AUTOSAR XML (schema 4-0-3)
package /ComponentTypes
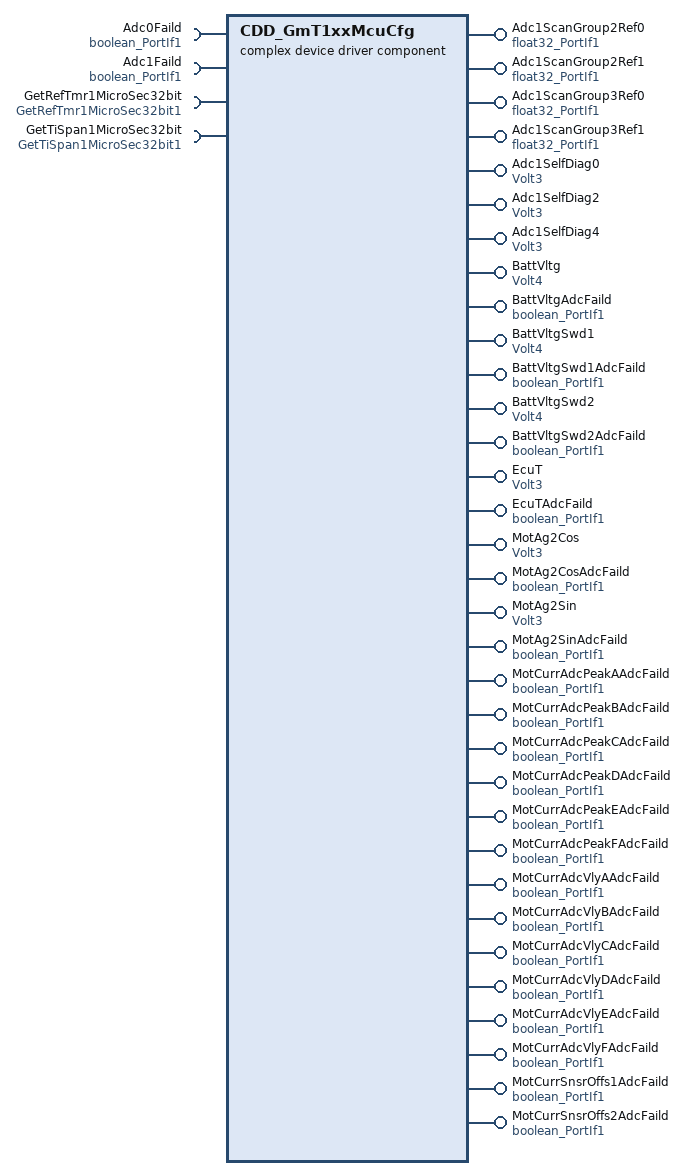
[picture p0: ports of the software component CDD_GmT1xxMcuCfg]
  complex device driver sw component type CDD_GmT1xxMcuCfg
    33 x provide port:
      Adc1ScanGroup2Ref0: nonqueued-sender-com-spec{data-element=Val, init-value=0}, provided-interface=float32_PortIf1
      Adc1ScanGroup2Ref1: nonqueued-sender-com-spec{data-element=Val, init-value=0}, provided-interface=float32_PortIf1
      Adc1ScanGroup3Ref0: nonqueued-sender-com-spec{data-element=Val, init-value=0}, provided-interface=float32_PortIf1
      Adc1ScanGroup3Ref1: nonqueued-sender-com-spec{data-element=Val, init-value=0}, provided-interface=float32_PortIf1
      Adc1SelfDiag0: nonqueued-sender-com-spec{data-element=Val, init-value=0}, provided-interface=Volt3
      Adc1SelfDiag2: nonqueued-sender-com-spec{data-element=Val, init-value=0}, provided-interface=Volt3
      Adc1SelfDiag4: nonqueued-sender-com-spec{data-element=Val, init-value=0}, provided-interface=Volt3
      BattVltg: nonqueued-sender-com-spec{data-element=Val, init-value=0}, provided-interface=Volt4
      BattVltgAdcFaild: nonqueued-sender-com-spec{data-element=Logl, init-value=0}, provided-interface=boolean_PortIf1
      BattVltgSwd1: nonqueued-sender-com-spec{data-element=Val, init-value=0}, provided-interface=Volt4
      BattVltgSwd1AdcFaild: nonqueued-sender-com-spec{data-element=Logl, init-value=0}, provided-interface=boolean_PortIf1
      BattVltgSwd2: nonqueued-sender-com-spec{data-element=Val, init-value=0}, provided-interface=Volt4
      BattVltgSwd2AdcFaild: nonqueued-sender-com-spec{data-element=Logl, init-value=0}, provided-interface=boolean_PortIf1
      EcuT: nonqueued-sender-com-spec{data-element=Val, init-value=0}, provided-interface=Volt3
      EcuTAdcFaild: nonqueued-sender-com-spec{data-element=Logl, init-value=0}, provided-interface=boolean_PortIf1
      MotAg2Cos: nonqueued-sender-com-spec{data-element=Val, init-value=0}, provided-interface=Volt3
      MotAg2CosAdcFaild: nonqueued-sender-com-spec{data-element=Logl, init-value=0}, provided-interface=boolean_PortIf1
      MotAg2Sin: nonqueued-sender-com-spec{data-element=Val, init-value=0}, provided-interface=Volt3
      MotAg2SinAdcFaild: nonqueued-sender-com-spec{data-element=Logl, init-value=0}, provided-interface=boolean_PortIf1
      MotCurrAdcPeakAAdcFaild: nonqueued-sender-com-spec{data-element=Logl, init-value=0}, provided-interface=boolean_PortIf1
      MotCurrAdcPeakBAdcFaild: nonqueued-sender-com-spec{data-element=Logl, init-value=0}, provided-interface=boolean_PortIf1
      MotCurrAdcPeakCAdcFaild: nonqueued-sender-com-spec{data-element=Logl, init-value=0}, provided-interface=boolean_PortIf1
      MotCurrAdcPeakDAdcFaild: nonqueued-sender-com-spec{data-element=Logl, init-value=0}, provided-interface=boolean_PortIf1
      MotCurrAdcPeakEAdcFaild: nonqueued-sender-com-spec{data-element=Logl, init-value=0}, provided-interface=boolean_PortIf1
      MotCurrAdcPeakFAdcFaild: nonqueued-sender-com-spec{data-element=Logl, init-value=0}, provided-interface=boolean_PortIf1
      MotCurrAdcVlyAAdcFaild: nonqueued-sender-com-spec{data-element=Logl, init-value=0}, provided-interface=boolean_PortIf1
      MotCurrAdcVlyBAdcFaild: nonqueued-sender-com-spec{data-element=Logl, init-value=0}, provided-interface=boolean_PortIf1
      MotCurrAdcVlyCAdcFaild: nonqueued-sender-com-spec{data-element=Logl, init-value=0}, provided-interface=boolean_PortIf1
      MotCurrAdcVlyDAdcFaild: nonqueued-sender-com-spec{data-element=Logl, init-value=0}, provided-interface=boolean_PortIf1
      MotCurrAdcVlyEAdcFaild: nonqueued-sender-com-spec{data-element=Logl, init-value=0}, provided-interface=boolean_PortIf1
      MotCurrAdcVlyFAdcFaild: nonqueued-sender-com-spec{data-element=Logl, init-value=0}, provided-interface=boolean_PortIf1
      MotCurrSnsrOffs1AdcFaild: nonqueued-sender-com-spec{data-element=Logl, init-value=0}, provided-interface=boolean_PortIf1
      MotCurrSnsrOffs2AdcFaild: nonqueued-sender-com-spec{data-element=Logl, init-value=0}, provided-interface=boolean_PortIf1
    4 x require port:
      Adc0Faild: nonqueued-receiver-com-spec{data-element=Logl, filter=data-filter-type=ALWAYS, init-value=0}, required-interface=boolean_PortIf1
      Adc1Faild: nonqueued-receiver-com-spec{data-element=Logl, filter=data-filter-type=ALWAYS, init-value=0}, required-interface=boolean_PortIf1
      GetRefTmr1MicroSec32bit: required-interface=GetRefTmr1MicroSec32bit1
      GetTiSpan1MicroSec32bit: required-interface=GetTiSpan1MicroSec32bit1
    behavior CDD_GmT1xxMcuCfg_InternalBehavior: data-type-mapping=Nexteer
      6 x timing event:
        CDD_GmT1xxMcuCfg_InitEvent: start-on-event=GmT1xxMcuCfgInit1, period=0
        CDD_GmT1xxMcuCfg_Init_2_InitEvent: start-on-event=GmT1xxMcuCfgInit2, period=0
        CDD_GmT1xxMcuCfg_Init_1_InitEvent: start-on-event=GmT1xxMcuCfgInit3, period=0
        TMT_GmT1xxMcuCfgPer{2..4}: start-on-event=GmT1xxMcuCfgPer{2..4}, period=0.002
      6 x runnable:
        GmT1xxMcuCfgInit1
        GmT1xxMcuCfgInit2
          sync call SC_GetRefTmr1MicroSec32bit_Oper: operation=GetRefTmr1MicroSec32bit.Oper, timeout=0
          sync call SC_GetTiSpan1MicroSec32bit_Oper: operation=GetTiSpan1MicroSec32bit.Oper, timeout=0
        GmT1xxMcuCfgInit3
          data-send-points:
            9 x access:
              SEND_Adc1SelfDiag0_Val: accessed-variable=Adc1SelfDiag0.Val
              SEND_Adc1SelfDiag2_Val: accessed-variable=Adc1SelfDiag2.Val
              SEND_Adc1SelfDiag4_Val: accessed-variable=Adc1SelfDiag4.Val
              SEND_BattVltg_Val: accessed-variable=BattVltg.Val
              SEND_BattVltgSwd1_Val: accessed-variable=BattVltgSwd1.Val
              SEND_BattVltgSwd2_Val: accessed-variable=BattVltgSwd2.Val
              SEND_EcuT_Val: accessed-variable=EcuT.Val
              SEND_MotAg2Cos_Val: accessed-variable=MotAg2Cos.Val
              SEND_MotAg2Sin_Val: accessed-variable=MotAg2Sin.Val
        GmT1xxMcuCfgPer2
          data-send-points:
            13 x access:
              SEND_Adc1ScanGroup2Ref0_Val: accessed-variable=Adc1ScanGroup2Ref0.Val
              SEND_Adc1ScanGroup2Ref1_Val: accessed-variable=Adc1ScanGroup2Ref1.Val
              SEND_Adc1ScanGroup3Ref0_Val: accessed-variable=Adc1ScanGroup3Ref0.Val
              SEND_Adc1ScanGroup3Ref1_Val: accessed-variable=Adc1ScanGroup3Ref1.Val
              SEND_Adc1SelfDiag0_Val: accessed-variable=Adc1SelfDiag0.Val
              SEND_Adc1SelfDiag2_Val: accessed-variable=Adc1SelfDiag2.Val
              SEND_Adc1SelfDiag4_Val: accessed-variable=Adc1SelfDiag4.Val
              SEND_BattVltg_Val: accessed-variable=BattVltg.Val
              SEND_BattVltgSwd1_Val: accessed-variable=BattVltgSwd1.Val
              SEND_BattVltgSwd2_Val: accessed-variable=BattVltgSwd2.Val
              SEND_EcuT_Val: accessed-variable=EcuT.Val
              SEND_MotAg2Cos_Val: accessed-variable=MotAg2Cos.Val
              SEND_MotAg2Sin_Val: accessed-variable=MotAg2Sin.Val
        GmT1xxMcuCfgPer3
          data-receive-point-by-arguments:
            access REC_Adc0Faild_Logl: accessed-variable=Adc0Faild.Logl
            access REC_Adc1Faild_Logl: accessed-variable=Adc1Faild.Logl
          data-send-points:
            20 x access:
              SEND_BattVltgAdcFaild_Logl: accessed-variable=BattVltgAdcFaild.Logl
              SEND_BattVltgSwd1AdcFaild_Logl: accessed-variable=BattVltgSwd1AdcFaild.Logl
              SEND_BattVltgSwd2AdcFaild_Logl: accessed-variable=BattVltgSwd2AdcFaild.Logl
              SEND_EcuTAdcFaild_Logl: accessed-variable=EcuTAdcFaild.Logl
              SEND_MotAg2CosAdcFaild_Logl: accessed-variable=MotAg2CosAdcFaild.Logl
              SEND_MotAg2SinAdcFaild_Logl: accessed-variable=MotAg2SinAdcFaild.Logl
              SEND_MotCurrAdcPeakAAdcFaild_Logl: accessed-variable=MotCurrAdcPeakAAdcFaild.Logl
              SEND_MotCurrAdcPeakBAdcFaild_Logl: accessed-variable=MotCurrAdcPeakBAdcFaild.Logl
              SEND_MotCurrAdcPeakCAdcFaild_Logl: accessed-variable=MotCurrAdcPeakCAdcFaild.Logl
              SEND_MotCurrAdcPeakDAdcFaild_Logl: accessed-variable=MotCurrAdcPeakDAdcFaild.Logl
              SEND_MotCurrAdcPeakEAdcFaild_Logl: accessed-variable=MotCurrAdcPeakEAdcFaild.Logl
              SEND_MotCurrAdcPeakFAdcFaild_Logl: accessed-variable=MotCurrAdcPeakFAdcFaild.Logl
              SEND_MotCurrAdcVlyAAdcFaild_Logl: accessed-variable=MotCurrAdcVlyAAdcFaild.Logl
              SEND_MotCurrAdcVlyBAdcFaild_Logl: accessed-variable=MotCurrAdcVlyBAdcFaild.Logl
              SEND_MotCurrAdcVlyCAdcFaild_Logl: accessed-variable=MotCurrAdcVlyCAdcFaild.Logl
              SEND_MotCurrAdcVlyDAdcFaild_Logl: accessed-variable=MotCurrAdcVlyDAdcFaild.Logl
              SEND_MotCurrAdcVlyEAdcFaild_Logl: accessed-variable=MotCurrAdcVlyEAdcFaild.Logl
              SEND_MotCurrAdcVlyFAdcFaild_Logl: accessed-variable=MotCurrAdcVlyFAdcFaild.Logl
              SEND_MotCurrSnsrOffs1AdcFaild_Logl: accessed-variable=MotCurrSnsrOffs1AdcFaild.Logl
              SEND_MotCurrSnsrOffs2AdcFaild_Logl: accessed-variable=MotCurrSnsrOffs2AdcFaild.Logl
        GmT1xxMcuCfgPer4
          sync call SC_GetRefTmr1MicroSec32bit_Oper: operation=GetRefTmr1MicroSec32bit.Oper, timeout=0
          sync call SC_GetTiSpan1MicroSec32bit_Oper: operation=GetTiSpan1MicroSec32bit.Oper, timeout=0
  swc implementation CDD_GmT1xxMcuCfg_Implementation: behavior=CDD_GmT1xxMcuCfg_InternalBehavior
    code-descriptors:
      code Default: artifact-descriptors=autosar-engineering-object={short-label=Default, category=SWSRC}
